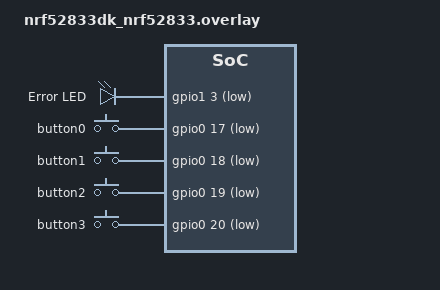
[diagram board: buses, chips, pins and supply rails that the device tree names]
// To get started, press Ctrl+Space to bring up the completion menu and view the available nodes.

// You can also use the buttons in the sidebar to perform actions on nodes.
// Actions currently available include:

// * Enabling / disabling the node
// * Adding the bus to a bus
// * Removing the node
// * Connecting ADC channels

// For more help, browse the DeviceTree documentation at https://docs.zephyrproject.org/latest/guides/dts/index.html
// You can also visit the nRF DeviceTree extension documentation at https://nrfconnect.github.io/vscode-nrf-connect/devicetree/nrfdevicetree.html
/ {
    aliases {
        heartbeat = &led0;
        buzzer = &led1;
        ivdrip = &led2;
        alarm = &led3;
        error = &led4;
        button0 = &button0_pin; //sleep
        button1 = &button1_pin; //freq_up
        button2 = &button2_pin; //freq_down
        button3 = &button3_pin; //reset
    };

    leds {
        compatible = "gpio-leds";
        led4: led_4 {
            gpios = <&gpio1 3 GPIO_ACTIVE_LOW>;
            label = "Error LED";
        };
    };

    buttons {
        compatible = "gpio-keys";

        button0_pin: button_0 {
            label = "button0";
            gpios = <&gpio0 17 (GPIO_PULL_UP | GPIO_ACTIVE_LOW)>;
        };

        button1_pin: button_1 {
            label = "button1";
            gpios = <&gpio0 18 (GPIO_PULL_UP | GPIO_ACTIVE_LOW)>;
        };

        button2_pin: button_2 {
            label = "button2";
            gpios = <&gpio0 19 (GPIO_PULL_UP | GPIO_ACTIVE_LOW)>;
        };

        button3_pin: button_3 {
            label = "button3";
            gpios = <&gpio0 20 (GPIO_PULL_UP | GPIO_ACTIVE_LOW)>;
        };
    };
};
